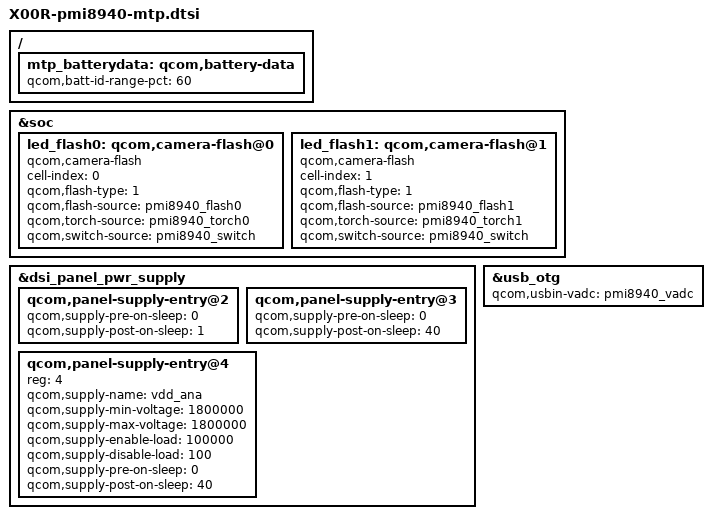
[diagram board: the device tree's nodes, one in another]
/*
 * Copyright (c) 2015-2018, The Linux Foundation. All rights reserved.
 *
 * This program is free software; you can redistribute it and/or modify
 * it under the terms of the GNU General Public License version 2 and
 * only version 2 as published by the Free Software Foundation.
 *
 * This program is distributed in the hope that it will be useful,
 * but WITHOUT ANY WARRANTY; without even the implied warranty of
 * MERCHANTABILITY or FITNESS FOR A PARTICULAR PURPOSE.  See the
 * GNU General Public License for more details.
 */

&soc {
	/delete-node/ qcom,camera-flash;

	led_flash0: qcom,camera-flash@0 {
		cell-index = <0>;
		compatible = "qcom,camera-flash";
		qcom,flash-type = <1>;
		qcom,flash-source = <&pmi8940_flash0>;
		qcom,torch-source = <&pmi8940_torch0>;
		qcom,switch-source = <&pmi8940_switch>;
		status = "ok";
	};
	
	led_flash1: qcom,camera-flash@1 {
		cell-index = <1>;
		compatible = "qcom,camera-flash";
		qcom,flash-type = <1>;
		qcom,flash-source = <&pmi8940_flash1>;
		qcom,torch-source = <&pmi8940_torch1>;
		qcom,switch-source = <&pmi8940_switch>;
		status = "ok";
	};
};

/{
	/delete-node/ qcom,battery-data;

	mtp_batterydata: qcom,battery-data {
		qcom,batt-id-range-pct = <60>;

		#include "battery/3308404_Wind_A305cos_3000mAh_averaged_MasterSlave_Feb26th2018_PMI8940.dtsi"
	};
};

&dsi_panel_pwr_supply {
	qcom,panel-supply-entry@2 {
		qcom,supply-pre-on-sleep =<0>; 
		qcom,supply-post-on-sleep =<1>;
	};

	qcom,panel-supply-entry@3 {
		qcom,supply-pre-on-sleep = <0>; 
		qcom,supply-post-on-sleep = <40>;
	};

	qcom,panel-supply-entry@4 {
		reg = <4>;
		qcom,supply-name = "vdd_ana";
		qcom,supply-min-voltage = <1800000>;
		qcom,supply-max-voltage = <1800000>;
		qcom,supply-enable-load = <100000>;
		qcom,supply-disable-load = <100>;
		qcom,supply-pre-on-sleep = <0>; 
		qcom,supply-post-on-sleep = <40>;
	};
};

&usb_otg {
	qcom,usbin-vadc = <&pmi8940_vadc>;
};
